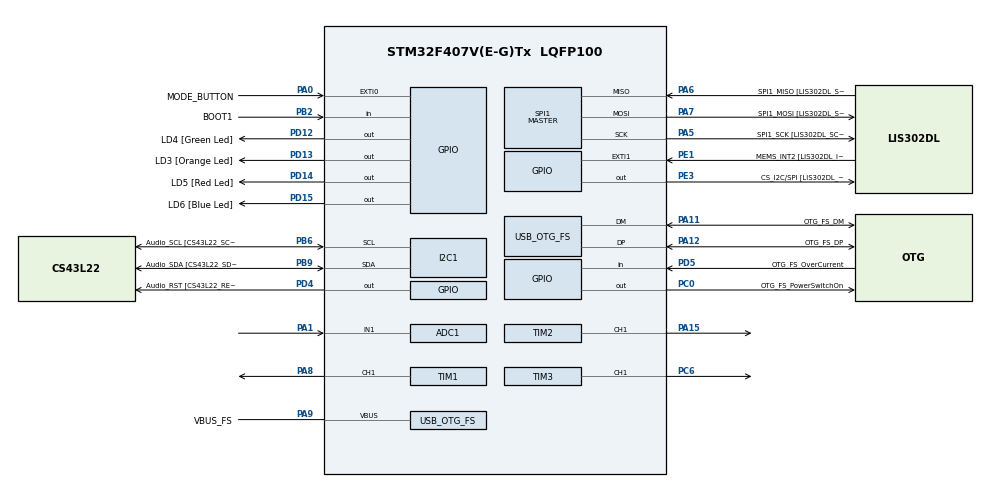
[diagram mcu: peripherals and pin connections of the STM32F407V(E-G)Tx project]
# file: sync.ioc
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ADC1.Channel-0\#ChannelRegularConversion=ADC_CHANNEL_1
ADC1.NbrOfConversionFlag=1
ADC1.Rank-0\#ChannelRegularConversion=1
ADC1.SamplingTime-0\#ChannelRegularConversion=ADC_SAMPLETIME_3CYCLES
ADC1.master=1
Dma.ADC1.1.Direction=DMA_PERIPH_TO_MEMORY
Dma.ADC1.1.FIFOMode=DMA_FIFOMODE_DISABLE
Dma.ADC1.1.Instance=DMA2_Stream0
Dma.ADC1.1.MemDataAlignment=DMA_MDATAALIGN_HALFWORD
Dma.ADC1.1.MemInc=DMA_MINC_ENABLE
Dma.ADC1.1.Mode=DMA_NORMAL
Dma.ADC1.1.PeriphDataAlignment=DMA_PDATAALIGN_HALFWORD
Dma.ADC1.1.PeriphInc=DMA_PINC_DISABLE
Dma.ADC1.1.Priority=DMA_PRIORITY_LOW
Dma.Request0=TIM1_CH1
Dma.Request1=ADC1
Dma.TIM1_CH1.0.Direction=DMA_MEMORY_TO_PERIPH
Dma.TIM1_CH1.0.FIFOMode=DMA_FIFOMODE_DISABLE
Dma.TIM1_CH1.0.Instance=DMA2_Stream1
Dma.TIM1_CH1.0.MemDataAlignment=DMA_MDATAALIGN_HALFWORD
Dma.TIM1_CH1.0.MemInc=DMA_MINC_ENABLE
Dma.TIM1_CH1.0.Mode=DMA_NORMAL
Dma.TIM1_CH1.0.PeriphDataAlignment=DMA_PDATAALIGN_HALFWORD
Dma.TIM1_CH1.0.PeriphInc=DMA_PINC_DISABLE
Dma.TIM1_CH1.0.Priority=DMA_PRIORITY_HIGH
Mcu.Family=STM32F4
Mcu.Name=STM32F407V(E-G)Tx
Mcu.Package=LQFP100
NVIC.DMA2_Stream0_IRQn=true\:0\:0\:false\:false\:true\:false\:true\:true
NVIC.DMA2_Stream1_IRQn=true\:0\:0\:false\:false\:true\:false\:true\:true
NVIC.EXTI0_IRQn=true\:0\:0\:false\:false\:true\:true\:true\:true
NVIC.OTG_FS_IRQn=true\:0\:0\:false\:false\:true\:true\:true\:true
NVIC.PriorityGroup=NVIC_PRIORITYGROUP_0
NVIC.TIM3_IRQn=true\:0\:0\:false\:false\:true\:true\:true\:true
PA0-WKUP.GPIO_Label=MODE_BUTTON
PA0-WKUP.Signal=GPXTI0
PA1.Signal=ADCx_IN1
PA10.GPIO_Label=OTG_FS_ID
PA10.GPIO_Mode=GPIO_MODE_AF_PP
PA10.GPIO_PuPd=GPIO_NOPULL
PA10.GPIO_Speed=GPIO_SPEED_FREQ_LOW
PA10.Signal=USB_OTG_FS_ID
PA11.GPIO_Label=OTG_FS_DM
PA11.GPIO_Mode=GPIO_MODE_AF_PP
PA11.GPIO_PuPd=GPIO_NOPULL
PA11.GPIO_Speed=GPIO_SPEED_FREQ_LOW
PA11.Mode=Host_Only
PA11.Signal=USB_OTG_FS_DM
PA12.GPIO_Label=OTG_FS_DP
PA12.GPIO_Mode=GPIO_MODE_AF_PP
PA12.GPIO_PuPd=GPIO_NOPULL
PA12.GPIO_Speed=GPIO_SPEED_FREQ_LOW
PA12.Mode=Host_Only
PA12.Signal=USB_OTG_FS_DP
PA13.GPIO_Label=SWDIO
PA13.Mode=Serial_Wire
PA13.Signal=SYS_JTMS-SWDIO
PA14.GPIO_Label=SWCLK
PA14.Mode=Serial_Wire
PA14.Signal=SYS_JTCK-SWCLK
PA15.Signal=S_TIM2_CH1_ETR
PA4.GPIO_Label=I2S3_WS [CS43L22_LRCK]
PA4.GPIO_Mode=GPIO_MODE_AF_PP
PA4.GPIO_PuPd=GPIO_NOPULL
PA4.GPIO_Speed=GPIO_SPEED_FREQ_LOW
PA4.Signal=I2S3_WS
PA5.GPIO_Label=SPI1_SCK [LIS302DL_SCL/SPC]
PA5.GPIO_Mode=GPIO_MODE_AF_PP
PA5.GPIO_PuPd=GPIO_NOPULL
PA5.GPIO_Speed=GPIO_SPEED_FREQ_LOW
PA5.Mode=Full_Duplex_Master
PA5.Signal=SPI1_SCK
PA6.GPIO_Label=SPI1_MISO [LIS302DL_SDO]
PA6.GPIO_Mode=GPIO_MODE_AF_PP
PA6.GPIO_PuPd=GPIO_NOPULL
PA6.GPIO_Speed=GPIO_SPEED_FREQ_LOW
PA6.Mode=Full_Duplex_Master
PA6.Signal=SPI1_MISO
PA7.GPIO_Label=SPI1_MOSI [LIS302DL_SDA/SDI/SDO]
PA7.GPIO_Mode=GPIO_MODE_AF_PP
PA7.GPIO_PuPd=GPIO_NOPULL
PA7.GPIO_Speed=GPIO_SPEED_FREQ_LOW
PA7.Mode=Full_Duplex_Master
PA7.Signal=SPI1_MOSI
PA8.Signal=S_TIM1_CH1
PA9.GPIO_Label=VBUS_FS
PA9.GPIO_Mode=GPIO_MODE_INPUT
PA9.GPIO_PuPd=GPIO_NOPULL
PA9.Mode=Activate_VBUS
PA9.Signal=USB_OTG_FS_VBUS
PB10.GPIO_Label=CLK_IN [MP45DT02_CLK]
PB10.GPIO_Mode=GPIO_MODE_AF_PP
PB10.GPIO_PuPd=GPIO_NOPULL
PB10.GPIO_Speed=GPIO_SPEED_FREQ_LOW
PB10.Signal=I2S2_CK
PB2.GPIO_Label=BOOT1
PB2.GPIO_Mode=GPIO_MODE_INPUT
PB2.GPIO_PuPd=GPIO_NOPULL
PB2.Signal=GPIO_Input
PB3.GPIO_Label=SWO
PB3.Signal=SYS_JTDO-SWO
PB6.GPIO_Label=Audio_SCL [CS43L22_SCL]
PB6.GPIO_Mode=GPIO_MODE_AF_OD
PB6.GPIO_Pu=GPIO_PULLUP
PB6.GPIO_PuPd=GPIO_NOPULL
PB6.GPIO_Speed=GPIO_SPEED_FREQ_LOW
PB6.Mode=I2C
PB6.Signal=I2C1_SCL
PB9.GPIO_Label=Audio_SDA [CS43L22_SDA]
PB9.GPIO_Mode=GPIO_MODE_AF_OD
PB9.GPIO_Pu=GPIO_PULLUP
PB9.GPIO_PuPd=GPIO_NOPULL
PB9.GPIO_Speed=GPIO_SPEED_FREQ_LOW
PB9.Mode=I2C
PB9.Signal=I2C1_SDA
PC0.GPIO_Label=OTG_FS_PowerSwitchOn
PC0.GPIO_PuPd=GPIO_NOPULL
PC0.GPIO_Speed=GPIO_SPEED_FREQ_LOW
PC0.PinState=GPIO_PIN_SET
PC0.Signal=GPIO_Output
PC10.GPIO_Label=I2S3_SCK [CS43L22_SCLK]
PC10.GPIO_Mode=GPIO_MODE_AF_PP
PC10.GPIO_PuPd=GPIO_NOPULL
PC10.GPIO_Speed=GPIO_SPEED_FREQ_LOW
PC10.Signal=I2S3_CK
PC12.GPIO_Label=I2S3_SD [CS43L22_SDIN]
PC12.GPIO_Mode=GPIO_MODE_AF_PP
PC12.GPIO_PuPd=GPIO_NOPULL
PC12.GPIO_Speed=GPIO_SPEED_FREQ_LOW
PC12.Signal=I2S3_SD
PC14-OSC32_IN.GPIO_Label=PC14-OSC32_IN
PC14-OSC32_IN.Mode=LSE-External-Oscillator
PC14-OSC32_IN.Signal=RCC_OSC32_IN
PC15-OSC32_OUT.GPIO_Label=PC15-OSC32_OUT
PC15-OSC32_OUT.Mode=LSE-External-Oscillator
PC15-OSC32_OUT.Signal=RCC_OSC32_OUT
PC3.GPIO_Label=PDM_OUT [MP45DT02_DOUT]
PC3.GPIO_Mode=GPIO_MODE_AF_PP
PC3.GPIO_PuPd=GPIO_NOPULL
PC3.GPIO_Speed=GPIO_SPEED_FREQ_LOW
PC3.Signal=I2S2_SD
PC6.Signal=S_TIM3_CH1
PC7.GPIO_Label=I2S3_MCK [CS43L22_MCLK]
PC7.GPIO_Mode=GPIO_MODE_AF_PP
PC7.GPIO_PuPd=GPIO_NOPULL
PC7.GPIO_Speed=GPIO_SPEED_FREQ_LOW
PC7.Signal=I2S3_MCK
PD12.GPIO_Label=LD4 [Green Led]
PD12.GPIO_PuPd=GPIO_NOPULL
PD12.GPIO_Speed=GPIO_SPEED_FREQ_LOW
PD12.Signal=GPIO_Output
PD13.GPIO_Label=LD3 [Orange Led]
PD13.GPIO_PuPd=GPIO_NOPULL
PD13.GPIO_Speed=GPIO_SPEED_FREQ_LOW
PD13.Signal=GPIO_Output
PD14.GPIO_Label=LD5 [Red Led]
PD14.GPIO_PuPd=GPIO_NOPULL
PD14.GPIO_Speed=GPIO_SPEED_FREQ_LOW
PD14.Signal=GPIO_Output
PD15.GPIO_Label=LD6 [Blue Led]
PD15.GPIO_PuPd=GPIO_NOPULL
PD15.GPIO_Speed=GPIO_SPEED_FREQ_LOW
PD15.Signal=GPIO_Output
PD4.GPIO_Label=Audio_RST [CS43L22_RESET]
PD4.GPIO_PuPd=GPIO_NOPULL
PD4.GPIO_Speed=GPIO_SPEED_FREQ_LOW
PD4.Signal=GPIO_Output
PD5.GPIO_Label=OTG_FS_OverCurrent
PD5.GPIO_Mode=GPIO_MODE_INPUT
PD5.GPIO_PuPd=GPIO_NOPULL
PD5.Signal=GPIO_Input
PE1.GPIO_Label=MEMS_INT2 [LIS302DL_INT2]
PE1.GPIO_ModeDefaultEXTI=GPIO_MODE_EVT_RISING
PE1.GPIO_PuPd=GPIO_NOPULL
PE1.Signal=GPXTI1
PE3.GPIO_Label=CS_I2C/SPI [LIS302DL_CS_I2C/SPI]
PE3.GPIO_PuPd=GPIO_NOPULL
PE3.GPIO_Speed=GPIO_SPEED_FREQ_LOW
PE3.Signal=GPIO_Output
PH0-OSC_IN.GPIO_Label=PH0-OSC_IN
PH0-OSC_IN.Mode=HSE-External-Oscillator
PH0-OSC_IN.Signal=RCC_OSC_IN
PH1-OSC_OUT.GPIO_Label=PH1-OSC_OUT
PH1-OSC_OUT.Mode=HSE-External-Oscillator
PH1-OSC_OUT.Signal=RCC_OSC_OUT
ProjectManager.HeapSize=0x200
ProjectManager.StackSize=0x400
ProjectManager.TargetToolchain=STM32CubeIDE
RCC.48MHZClocksFreq_Value=48000000
RCC.AHBFreq_Value=168000000
RCC.APB1CLKDivider=RCC_HCLK_DIV4
RCC.APB1Freq_Value=42000000
RCC.APB1TimFreq_Value=84000000
RCC.APB2CLKDivider=RCC_HCLK_DIV2
RCC.APB2Freq_Value=84000000
RCC.APB2TimFreq_Value=168000000
RCC.CortexFreq_Value=168000000
RCC.HCLKFreq_Value=168000000
RCC.HSE_VALUE=8000000
RCC.HSI_VALUE=16000000
RCC.PLLM=8
RCC.PLLN=336
RCC.PLLQ=7
RCC.SYSCLKFreq_VALUE=168000000
RCC.SYSCLKSource=RCC_SYSCLKSOURCE_PLLCLK
RCC.VCOOutputFreq_Value=336000000
SH.ADCx_IN1.0=ADC1_IN1,IN1
SH.S_TIM1_CH1.0=TIM1_CH1,PWM Generation1 CH1
SH.S_TIM2_CH1_ETR.0=TIM2_CH1,PWM Generation1 CH1
SH.S_TIM3_CH1.0=TIM3_CH1,PWM Generation1 CH1
SPI1.BaudRatePrescaler-Full_Duplex_Master=SPI_BAUDRATEPRESCALER_2
SPI1.CalculateBaudRate-Full_Duplex_Master=42.0 MBits/s
SPI1.Direction=SPI_DIRECTION_2LINES
SPI1.Mode=SPI_MODE_MASTER
SPI1.Mode-Full_Duplex_Master=SPI_MODE_MASTER
SPI1.VirtualType=VM_MASTER
TIM1.Channel-PWM\ Generation1\ CH1=TIM_CHANNEL_1
TIM1.Period=103
TIM2.AutoReloadPreload=TIM_AUTORELOAD_PRELOAD_ENABLE
TIM2.Channel-PWM\ Generation1\ CH1=TIM_CHANNEL_1
TIM2.Period=2248
TIM2.TIM_MasterOutputTrigger=TIM_TRGO_UPDATE
TIM3.Channel-PWM\ Generation1\ CH1=TIM_CHANNEL_1
TIM3.Period=59999
TIM3.Prescaler=41
USB_HOST.BSP.number=1
USB_HOST.USBH_HandleTypeDef-CDC_FS=hUsbHostFS
USB_HOST.VirtualModeFS=Cdc
USB_HOST0.BSP.STBoard=false
USB_HOST0.BSP.api=Unknown
USB_HOST0.BSP.instance=PC0
USB_HOST0.BSP.ip=GPIO
USB_HOST0.BSP.mode=Output
USB_HOST0.BSP.name=Drive_VBUS_FS
USB_HOST0.BSP.solution=PC0
USB_OTG_FS.VirtualMode=Host_Only
USB_OTG_FS.phy_itface=HCD_PHY_EMBEDDED
VP_TIM1_VS_ClockSourceINT.Mode=Internal
VP_TIM2_VS_ClockSourceINT.Mode=Internal
VP_TIM3_VS_ClockSourceINT.Mode=Internal
VP_USB_HOST_VS_USB_HOST_CDC_FS.Mode=CDC_FS
board=STM32F407G-DISC1

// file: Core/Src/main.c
#include "main.h"
#include "usb_host.h"

void SystemClock_Config(void);
#define TIMER_FREQ    72000000UL
#define TOTAL_CYCLES  90
#define T0H_CYCLES    30
#define T1H_CYCLES    60
#define RESET_SLOTS   50
#define MAX_LED		  84
#define USE_BRIGHTNESS 1
#define PI 3.14159265

ADC_HandleTypeDef hadc1;
DMA_HandleTypeDef hdma_adc1;
I2C_HandleTypeDef hi2c1;
SPI_HandleTypeDef hspi1;
TIM_HandleTypeDef htim1;
TIM_HandleTypeDef htim2;
TIM_HandleTypeDef htim3;
DMA_HandleTypeDef hdma_tim1_ch1;

static void MX_GPIO_Init(void);
static void MX_DMA_Init(void);
static void MX_I2C1_Init(void);
static void MX_SPI1_Init(void);
static void MX_ADC1_Init(void);
static void MX_TIM2_Init(void);
static void MX_TIM3_Init(void);
static void MX_TIM1_Init(void);
void MX_USB_HOST_Process(void);

#define LED_PER_BANDS 14
#define NUM_BANDS 6

uint8_t LED_Data[MAX_LED][4];
uint8_t LED_Mod[MAX_LED][4];

int datasentflag=0;
uint16_t pwmData[(24*MAX_LED)+50];

const uint8_t colors_pixel[14][3] = {
    {255, 0, 0},
    {255, 127, 0},
    {255, 255, 0},
    {0, 255, 0},
    {0, 255, 255},
    {0, 0, 255},
    {75, 0, 130},
    {255, 255, 255},
    {255, 182, 193},
    {255, 165, 0},
    {0, 191, 255},
    {255, 20, 147},
    {0, 128, 128},
    {128, 0, 128}
};
uint16_t effStep = 0;
uint16_t pixelPos = 0;
uint16_t colorIndex = 0;
uint16_t fadeStep = 0;

typedef enum {
    MODE_RAINBOW,
	MODE_FFT
} EffectMode;

EffectMode mode = MODE_RAINBOW;

uint8_t tick_divider,  count_tick = 0;
volatile uint8_t call_effect_flag= 0;

void HAL_TIM_PeriodElapsedCallback(TIM_HandleTypeDef *htim);
void HAL_TIM_PWM_PulseFinishedCallback(TIM_HandleTypeDef *htim);

void Set_Brightness (int brightness);
void Set_LED (int LEDnum, int Red, int Green, int Blue) ;
void Reset_LED (void);
void WS2812_Send(void);

uint8_t rainbow_effect();
uint8_t sync_effect();

//------------ Audio management section-----------------
#define ADC_MEAN   2048.0f
extern ADC_HandleTypeDef hadc1;

#define FFT_SIZE 256
uint16_t audioBuffer[FFT_SIZE * 2]; // 2 ping pong buffer
volatile uint8_t ready_buffer = 0;
volatile uint8_t current_buffer = 0;
//------------ End Audio management section-----------------
//-------------FFT define section----------------
#define ARM_MATH_CM4
#include "arm_math.h"

#define SAMPLE_RATE 8000

arm_rfft_fast_instance_f32 fftInstance;

typedef struct {
    uint16_t start_bin;
    uint16_t end_bin;
    float magnitude;
    uint8_t color[3];
} FrequencyBand;

FrequencyBand frequency_bands[NUM_BANDS];

float band_frequencies[NUM_BANDS + 1] = {
    20,    // end low bass, start bass
    150,
	250,   // end bass, start upper bass
	500,
    1000,   // end upper bass, start low mid
    2000,  // end low mid, start mid
    4000,  // end mid, start high mid
};
const uint8_t band_colors[NUM_BANDS][3] = {
    {255, 0, 0},    // Band 0: Red (Bass)
    {255, 127, 0},  // Band 1: Orange
    {255, 255, 0},  // Band 2: Yellow
    {0, 255, 0},    // Band 3: Green
    {0, 255, 255},  // Band 4: Cyan
    {0, 0, 255}     // Band 5: Blue
};

void FFT_INIT(void);
void FFT_PROCESS(void);
//-------------END FFT define section----------------

/**
 * @brief  Bass-reactive pulse: brightness & color based on sound level.
 * @retval 0x01 always, 0x00 on ADC error.
 */

#include <stdbool.h>
/**
 * @brief  Invoked by TIM3 interrupt: selects and runs current effect.
 */
void call_effect(void)
{

    call_effect_flag = 0;
    switch (mode)
    {
        case MODE_RAINBOW:
            tick_divider = 10;
            rainbow_effect();
            break;

        case MODE_FFT:
        	sync_effect();
            break;

        default:
            break;
    }
}
  // Bắt đầu chuyển đổi ADC để đọc cường độ âm thanh
//  HAL_ADC_Start(&hadc1);

  /* USER CODE END 2 */
  int main(void) {
	  HAL_Init();
	  SystemClock_Config();
	  MX_GPIO_Init();
	  MX_DMA_Init();
	  MX_I2C1_Init();
	  MX_SPI1_Init();
	  MX_USB_HOST_Init();
	  MX_ADC1_Init();
	  MX_TIM2_Init();
	  MX_TIM1_Init();
	  MX_TIM3_Init();

	  HAL_TIM_Base_Start(&htim2);
	  HAL_TIM_Base_Start_IT(&htim3);
	  FFT_INIT();
	  Reset_LED();
	  HAL_ADC_Start_DMA(&hadc1, (uint32_t*)audioBuffer, FFT_SIZE);

      mode = MODE_RAINBOW;

      while (1)
      {
          if (call_effect_flag)
        	  call_effect();

          HAL_Delay(5);
      }
  }

 // ===========LED transmission section ===========
void WS2812_Send(void) {
      uint32_t indx = 0;
      uint32_t color;

      for (int led = 0; led < MAX_LED; led++) {
  #if USE_BRIGHTNESS
          color = ((LED_Mod[led][1]<<16) | (LED_Mod[led][2]<<8) | LED_Mod[led][3]);
  #else
          color = ((LED_Data[led][1]<<16) | (LED_Data[led][2]<<8) | LED_Data[led][3]);
  #endif
          for (int bit = 23; bit >= 0; bit--) {
              pwmData[indx++] = (color & (1UL << bit)) ? T1H_CYCLES : T0H_CYCLES;
          }
      }

      for (int i = 0; i < RESET_SLOTS; i++) {
          pwmData[indx++] = 0;
      }

      HAL_GPIO_TogglePin(GPIOA, GPIO_PIN_5);
      HAL_TIM_PWM_Start_DMA(&htim1, TIM_CHANNEL_1, (uint32_t *)pwmData, indx);
      while (!datasentflag) {}
      datasentflag = 0;
}
void Reset_LED (void) {
      for (int i=0; i< MAX_LED; i++) {
    	  LED_Mod[i][0] = i;
          LED_Mod[i][1] = 0;
          LED_Mod[i][2] = 0;
          LED_Mod[i][3] = 0;
      }
}
void Set_Brightness (int brightness) {
#if USE_BRIGHTNESS
    if (brightness > 45) brightness = 45;
    for (int i=0; i < MAX_LED; i++) {
        LED_Mod[i][0] = LED_Data[i][0];
        for (int j=1; j<4; j++) {
            float angle = 90-brightness;
            angle = angle*PI / 180;
            LED_Mod[i][j] = (LED_Data[i][j])/(tan(angle));
        }
    }
#endif
}
void Set_LED (int LEDnum, int Red, int Green, int Blue) {
    LED_Mod[LEDnum][0] = LEDnum;
    LED_Mod[LEDnum][1] = Green;
    LED_Mod[LEDnum][2] = Red;
    LED_Mod[LEDnum][3] = Blue;
}
// ===========END LED transmission section===========
// ===========Custom callback section ================
void HAL_ADC_ConvCpltCallback(ADC_HandleTypeDef* hadc)
{
	current_buffer = !current_buffer;
	ready_buffer = 1;
	HAL_ADC_Start_DMA(&hadc1, (uint32_t*)&audioBuffer[current_buffer * FFT_SIZE], FFT_SIZE);
}

void HAL_TIM_PWM_PulseFinishedCallback(TIM_HandleTypeDef *htim) {
    HAL_TIM_PWM_Stop_DMA(&htim1, TIM_CHANNEL_1);
    datasentflag=1;
}
void HAL_TIM_PeriodElapsedCallback(TIM_HandleTypeDef *htim) {
		count_tick++;
	if (htim->Instance == TIM3 && tick_divider == count_tick ) {
		count_tick = 0;
		call_effect_flag = 1;

	}
}
void HAL_GPIO_EXTI_Callback(uint16_t GPIO_Pin)
{
      if(GPIO_Pin == GPIO_PIN_0) // INT Source is pin A9
      {
    	  mode = (EffectMode)((mode + 1) % 2);
      }
}
// =========== End Custom callback section===========
// =========== LED effect section ==================
uint8_t rainbow_effect() {
	    // Strip ID: 0 - Effect: Rainbow - LEDS: 8
	    // Steps: 13 - Delay: 54
	    // Colors: 3 (255.0.0, 0.255.0, 0.0.255)
	    // Options: rainbowlen=8, toLeft=true,
	//  if(millis() - strip_0.effStart < 54 * (strip_0.effStep)) return 0x00;

	  float factor1, factor2;
	  uint16_t ind;
	  for(uint16_t j=0;j< MAX_LED;j++) {
	    ind = effStep + j * 1.625;
	    switch((int)((ind % 13) / 4.333333333333333)) {
	      case 0: factor1 = 1.0 - ((float)(ind % 13 - 0 * 4.333333333333333) / 4.333333333333333);
	              factor2 = (float)((int)(ind - 0) % 13) / 4.333333333333333;
	              /************ chnaged here *********/
	              Set_LED(j, 255 * factor1 + 0 * factor2, 0 * factor1 + 255 * factor2, 0 * factor1 + 0 * factor2);
	              WS2812_Send();
	              break;
	      case 1: factor1 = 1.0 - ((float)(ind % 13 - 1 * 4.333333333333333) / 4.333333333333333);
	              factor2 = (float)((int)(ind - 4.333333333333333) % 13) / 4.333333333333333;
	              Set_LED(j, 0 * factor1 + 0 * factor2, 255 * factor1 + 0 * factor2, 0 * factor1 + 255 * factor2);
	              WS2812_Send();
	              break;
	      case 2: factor1 = 1.0 - ((float)(ind % 13 - 2 * 4.333333333333333) / 4.333333333333333);
	              factor2 = (float)((int)(ind - 8.666666666666666) % 13) / 4.333333333333333;
	              Set_LED(j, 0 * factor1 + 255 * factor2, 0 * factor1 + 0 * factor2, 255 * factor1 + 0 * factor2);
	              WS2812_Send();
	              break;
	    }
	  }
	  if(effStep >= 13) {effStep=0; return 0x03; }
	  else effStep++;
	  return 0x01;
	}
//----------------FFT subsection-----------------------
void FFT_INIT(void)
{
	arm_rfft_fast_init_f32(&fftInstance, FFT_SIZE);
	float freq_resolution = (float)SAMPLE_RATE / FFT_SIZE;

	for (int i = 0; i < NUM_BANDS; i++) {
	        frequency_bands[i].start_bin = (uint16_t)(band_frequencies[i] / freq_resolution);
	        frequency_bands[i].end_bin = (uint16_t)(band_frequencies[i + 1] / freq_resolution);
	        frequency_bands[i].magnitude = 0.0f;

	        frequency_bands[i].color[0] = band_colors[i][0];
	        frequency_bands[i].color[1] = band_colors[i][1];
	        frequency_bands[i].color[2] = band_colors[i][2];

	        if (frequency_bands[i].end_bin > FFT_SIZE/2)
	            frequency_bands[i].end_bin = FFT_SIZE/2;
	}
}

void FFT_PROCESS(void)
{
	float32_t inputBuffer[FFT_SIZE * 2],
			 outputBuffer[FFT_SIZE];
	float32_t fftBuffer[FFT_SIZE * 2];
	for (int i = 0; i < FFT_SIZE; i++) {
	        inputBuffer[i] = ((float32_t)audioBuffer[(!current_buffer) * FFT_SIZE + i] -  ADC_MEAN);
	        // normalize signal
	        inputBuffer[i] /= ADC_MEAN;
	    }
	    // Biến đổi RFFT
	    arm_rfft_fast_f32(&fftInstance, inputBuffer, fftBuffer, 0);

	    // Tính cường độ
	    arm_cmplx_mag_f32(fftBuffer, outputBuffer, FFT_SIZE / 2);
	    // TÍnh trung bình cường độ của mỗi band
	    for (int band = 0; band < NUM_BANDS; band++) {
	        float sum = 0.0f;
	        int bin_count = 0;

	        for (int bin = frequency_bands[band].start_bin; bin < frequency_bands[band].end_bin; bin++) {
	            if (bin < FFT_SIZE / 2) {
	                sum += outputBuffer[bin];
	                bin_count++;
	            }
	        }
	        float avg =  sum / bin_count;
	        if (bin_count > 0) {
	            frequency_bands[band].magnitude = avg;
	        }
	    }
	}

const float max_magnitude[NUM_BANDS] = {20.0f, 20.0f, 20.0f, 20.0f, 15.0f, 10.0f};
const float min_magnitude[NUM_BANDS] = {5.0f, 5.0f, 5.0f, 5.0, 2.5f, 1.0f};

uint8_t top_index[NUM_BANDS] ={0};

uint8_t sync_effect()
{
    if (!ready_buffer)
        return 0;

    FFT_PROCESS();
    ready_buffer = 0;

    const int leds_per_band = 14;
    for (int band = 0; band < NUM_BANDS; band++)
    {
        float magnitude = frequency_bands[band].magnitude;
        float max  = max_magnitude[band];
        // Clamp magnitude
        if (magnitude < 0.0f) magnitude = 0.0f;
        if (magnitude > max_magnitude[band]) magnitude = max_magnitude[band];

        // Calculate activate led
        int active_leds = (int)((magnitude / max) * leds_per_band);
        if (active_leds > leds_per_band) active_leds = leds_per_band;

        uint8_t r = (uint8_t)(band_colors[band][0]);
        uint8_t g = (uint8_t)(band_colors[band][1]);
        uint8_t b = (uint8_t)(band_colors[band][2]);

        if (top_index[band] <= active_leds)
        	top_index[band] = active_leds;
        else
        	top_index[band]--;
        // Bật LED theo cường độ
        for (int i = 0; i < leds_per_band; i++) {
            int led_index = leds_per_band * band + i;
            if (i < active_leds) {
                Set_LED(led_index, r, g, b);
            } else {
                Set_LED(led_index, 0, 0, 0);
            }
        }
        Set_LED(top_index[band], 155 , 155 , 155);
        WS2812_Send();
        HAL_Delay(5);
    }

    return 1;
}

  void SystemClock_Config(void)
  {
    RCC_OscInitTypeDef RCC_OscInitStruct = {0};
    RCC_ClkInitTypeDef RCC_ClkInitStruct = {0};

    /** Configure the main internal regulator output voltage
    */
    __HAL_RCC_PWR_CLK_ENABLE();
    __HAL_PWR_VOLTAGESCALING_CONFIG(PWR_REGULATOR_VOLTAGE_SCALE1);
    /** Initializes the RCC Oscillators according to the specified parameters
    * in the RCC_OscInitTypeDef structure.
    */
    RCC_OscInitStruct.OscillatorType = RCC_OSCILLATORTYPE_HSE;
    RCC_OscInitStruct.HSEState = RCC_HSE_BYPASS;
    RCC_OscInitStruct.PLL.PLLState = RCC_PLL_ON;
    RCC_OscInitStruct.PLL.PLLSource = RCC_PLLSOURCE_HSE;
    RCC_OscInitStruct.PLL.PLLM = 4;
    RCC_OscInitStruct.PLL.PLLN = 72;
    RCC_OscInitStruct.PLL.PLLP = RCC_PLLP_DIV2;
    RCC_OscInitStruct.PLL.PLLQ = 2;
//    RCC_OscInitStruct.PLL.PLLM = 2;
    if (HAL_RCC_OscConfig(&RCC_OscInitStruct) != HAL_OK)
    {
      Error_Handler();
    }
    /** Initializes the CPU, AHB and APB buses clocks
    */
    RCC_ClkInitStruct.ClockType = RCC_CLOCKTYPE_HCLK|RCC_CLOCKTYPE_SYSCLK
                                |RCC_CLOCKTYPE_PCLK1|RCC_CLOCKTYPE_PCLK2;
    RCC_ClkInitStruct.SYSCLKSource = RCC_SYSCLKSOURCE_PLLCLK;
    RCC_ClkInitStruct.AHBCLKDivider = RCC_SYSCLK_DIV1;
    RCC_ClkInitStruct.APB1CLKDivider = RCC_HCLK_DIV2;
    RCC_ClkInitStruct.APB2CLKDivider = RCC_HCLK_DIV1;

    if (HAL_RCC_ClockConfig(&RCC_ClkInitStruct, FLASH_LATENCY_2) != HAL_OK)
    {
      Error_Handler();
    }
  }
static void MX_ADC1_Init(void)
{
	ADC_ChannelConfTypeDef sConfig = {0};

	    hadc1.Instance = ADC1;
	    hadc1.Init.ClockPrescaler = ADC_CLOCK_SYNC_PCLK_DIV4;      // ADC clock = 72MHz/4 = 18MHz
	    hadc1.Init.Resolution = ADC_RESOLUTION_12B;
	    hadc1.Init.ScanConvMode = DISABLE;
	    hadc1.Init.ContinuousConvMode = DISABLE;
	    hadc1.Init.DiscontinuousConvMode = DISABLE;
	    hadc1.Init.ExternalTrigConvEdge = ADC_EXTERNALTRIGCONVEDGE_RISING;
	    hadc1.Init.ExternalTrigConv = ADC_EXTERNALTRIGCONV_T2_TRGO; // Trigger từ TIM2
	    hadc1.Init.DataAlign = ADC_DATAALIGN_RIGHT;
	    hadc1.Init.NbrOfConversion = 1;
	    hadc1.Init.DMAContinuousRequests = ENABLE;                 // Cho phép DMA Circular
	    hadc1.Init.EOCSelection = ADC_EOC_SINGLE_CONV;
	    if (HAL_ADC_Init(&hadc1) != HAL_OK)
	    {
	        Error_Handler();
	    }

	    sConfig.Channel = ADC_CHANNEL_1;                  // Kênh ADC1_IN1 (PA1)
	    sConfig.Rank = 1;
	    sConfig.SamplingTime = ADC_SAMPLETIME_28CYCLES;   // 28 cycles
	    if (HAL_ADC_ConfigChannel(&hadc1, &sConfig) != HAL_OK)
	    {
	        Error_Handler();
	    }
}

static void MX_I2C1_Init(void)
{

  hi2c1.Instance = I2C1;
  hi2c1.Init.ClockSpeed = 100000;
  hi2c1.Init.DutyCycle = I2C_DUTYCYCLE_2;
  hi2c1.Init.OwnAddress1 = 0;
  hi2c1.Init.AddressingMode = I2C_ADDRESSINGMODE_7BIT;
  hi2c1.Init.DualAddressMode = I2C_DUALADDRESS_DISABLE;
  hi2c1.Init.OwnAddress2 = 0;
  hi2c1.Init.GeneralCallMode = I2C_GENERALCALL_DISABLE;
  hi2c1.Init.NoStretchMode = I2C_NOSTRETCH_DISABLE;
  if (HAL_I2C_Init(&hi2c1) != HAL_OK)
  {
    Error_Handler();
  }

}

static void MX_SPI1_Init(void)
{

  hspi1.Instance = SPI1;
  hspi1.Init.Mode = SPI_MODE_MASTER;
  hspi1.Init.Direction = SPI_DIRECTION_2LINES;
  hspi1.Init.DataSize = SPI_DATASIZE_8BIT;
  hspi1.Init.CLKPolarity = SPI_POLARITY_LOW;
  hspi1.Init.CLKPhase = SPI_PHASE_1EDGE;
  hspi1.Init.NSS = SPI_NSS_SOFT;
  hspi1.Init.BaudRatePrescaler = SPI_BAUDRATEPRESCALER_2;
  hspi1.Init.FirstBit = SPI_FIRSTBIT_MSB;
  hspi1.Init.TIMode = SPI_TIMODE_DISABLE;
  hspi1.Init.CRCCalculation = SPI_CRCCALCULATION_DISABLE;
  hspi1.Init.CRCPolynomial = 10;
  if (HAL_SPI_Init(&hspi1) != HAL_OK)
  {
    Error_Handler();
  }

}

static void MX_TIM1_Init(void)
{

  TIM_ClockConfigTypeDef sClockSourceConfig = {0};
  TIM_MasterConfigTypeDef sMasterConfig = {0};
  TIM_OC_InitTypeDef sConfigOC = {0};
  TIM_BreakDeadTimeConfigTypeDef sBreakDeadTimeConfig = {0};

  htim1.Instance = TIM1;
  htim1.Init.Prescaler = 0;
  htim1.Init.CounterMode = TIM_COUNTERMODE_UP;
  htim1.Init.Period = 90-1;
  htim1.Init.ClockDivision = TIM_CLOCKDIVISION_DIV1;
  htim1.Init.RepetitionCounter = 0;
  htim1.Init.AutoReloadPreload = TIM_AUTORELOAD_PRELOAD_DISABLE;
  if (HAL_TIM_Base_Init(&htim1) != HAL_OK)
  {
    Error_Handler();
  }
  sClockSourceConfig.ClockSource = TIM_CLOCKSOURCE_INTERNAL;
  if (HAL_TIM_ConfigClockSource(&htim1, &sClockSourceConfig) != HAL_OK)
  {
    Error_Handler();
  }
  if (HAL_TIM_PWM_Init(&htim1) != HAL_OK)
  {
    Error_Handler();
  }
  sMasterConfig.MasterOutputTrigger = TIM_TRGO_RESET;
  sMasterConfig.MasterSlaveMode = TIM_MASTERSLAVEMODE_DISABLE;
  if (HAL_TIMEx_MasterConfigSynchronization(&htim1, &sMasterConfig) != HAL_OK)
  {
    Error_Handler();
  }
  sConfigOC.OCMode = TIM_OCMODE_PWM1;
  sConfigOC.Pulse = 0;
  sConfigOC.OCPolarity = TIM_OCPOLARITY_HIGH;
  sConfigOC.OCNPolarity = TIM_OCNPOLARITY_HIGH;
  sConfigOC.OCFastMode = TIM_OCFAST_DISABLE;
  sConfigOC.OCIdleState = TIM_OCIDLESTATE_RESET;
  sConfigOC.OCNIdleState = TIM_OCNIDLESTATE_RESET;
  if (HAL_TIM_PWM_ConfigChannel(&htim1, &sConfigOC, TIM_CHANNEL_1) != HAL_OK)
  {
    Error_Handler();
  }
  sBreakDeadTimeConfig.OffStateRunMode = TIM_OSSR_DISABLE;
  sBreakDeadTimeConfig.OffStateIDLEMode = TIM_OSSI_DISABLE;
  sBreakDeadTimeConfig.LockLevel = TIM_LOCKLEVEL_OFF;
  sBreakDeadTimeConfig.DeadTime = 0;
  sBreakDeadTimeConfig.BreakState = TIM_BREAK_DISABLE;
  sBreakDeadTimeConfig.BreakPolarity = TIM_BREAKPOLARITY_HIGH;
  sBreakDeadTimeConfig.AutomaticOutput = TIM_AUTOMATICOUTPUT_DISABLE;
  if (HAL_TIMEx_ConfigBreakDeadTime(&htim1, &sBreakDeadTimeConfig) != HAL_OK)
  {
    Error_Handler();
  }
  HAL_TIM_MspPostInit(&htim1);

}

static void MX_TIM2_Init(void)
{
    TIM_ClockConfigTypeDef sClockSourceConfig = {0};
    TIM_MasterConfigTypeDef sMasterConfig = {0};

    htim2.Instance = TIM2;
    htim2.Init.Prescaler = 71;                   // 72MHz/72 = 1MHz
    htim2.Init.CounterMode = TIM_COUNTERMODE_UP;
    htim2.Init.Period = 124;                     // 1MHz/125 = 8000Hz → mỗi 125µs overflow
    htim2.Init.ClockDivision = TIM_CLOCKDIVISION_DIV1;
    htim2.Init.AutoReloadPreload = TIM_AUTORELOAD_PRELOAD_DISABLE;
    if (HAL_TIM_Base_Init(&htim2) != HAL_OK)
    {
        Error_Handler();
    }
    sClockSourceConfig.ClockSource = TIM_CLOCKSOURCE_INTERNAL;
    if (HAL_TIM_ConfigClockSource(&htim2, &sClockSourceConfig) != HAL_OK)
    {
        Error_Handler();
    }
    // Cho TIM2 tạo TRGO mỗi khi counter overflow (update event)
    sMasterConfig.MasterOutputTrigger = TIM_TRGO_UPDATE;
    sMasterConfig.MasterSlaveMode = TIM_MASTERSLAVEMODE_DISABLE;
    if (HAL_TIMEx_MasterConfigSynchronization(&htim2, &sMasterConfig) != HAL_OK)
    {
        Error_Handler();
    }
}

static void MX_TIM3_Init(void)
{

  TIM_ClockConfigTypeDef sClockSourceConfig = {0};
  TIM_MasterConfigTypeDef sMasterConfig = {0};
  TIM_OC_InitTypeDef sConfigOC = {0};
  TIM_BreakDeadTimeConfigTypeDef sBreakDeadTimeConfig = {0};

  htim3.Instance = TIM3;
  htim3.Init.Prescaler = 1;
  htim3.Init.CounterMode = TIM_COUNTERMODE_UP;
  htim3.Init.Period = 39999;
  htim3.Init.ClockDivision = TIM_CLOCKDIVISION_DIV1;
  htim3.Init.RepetitionCounter = 0;
  htim3.Init.AutoReloadPreload = TIM_AUTORELOAD_PRELOAD_ENABLE;
  if (HAL_TIM_Base_Init(&htim3) != HAL_OK)
  {
    Error_Handler();
  }
  sClockSourceConfig.ClockSource = TIM_CLOCKSOURCE_INTERNAL;
  if (HAL_TIM_ConfigClockSource(&htim3, &sClockSourceConfig) != HAL_OK)
  {
    Error_Handler();
  }
  if (HAL_TIM_PWM_Init(&htim3) != HAL_OK)
  {
    Error_Handler();
  }
  sMasterConfig.MasterOutputTrigger = TIM_TRGO_RESET;
  sMasterConfig.MasterSlaveMode = TIM_MASTERSLAVEMODE_DISABLE;
  if (HAL_TIMEx_MasterConfigSynchronization(&htim3, &sMasterConfig) != HAL_OK)
  {
    Error_Handler();
  }
  sConfigOC.OCMode = TIM_OCMODE_PWM1;
  sConfigOC.Pulse = 0;
  sConfigOC.OCPolarity = TIM_OCPOLARITY_HIGH;
  sConfigOC.OCNPolarity = TIM_OCNPOLARITY_HIGH;
  sConfigOC.OCFastMode = TIM_OCFAST_DISABLE;
  sConfigOC.OCIdleState = TIM_OCIDLESTATE_RESET;
  sConfigOC.OCNIdleState = TIM_OCNIDLESTATE_RESET;
  if (HAL_TIM_PWM_ConfigChannel(&htim3, &sConfigOC, TIM_CHANNEL_1) != HAL_OK)
  {
    Error_Handler();
  }
  sBreakDeadTimeConfig.OffStateRunMode = TIM_OSSR_DISABLE;
  sBreakDeadTimeConfig.OffStateIDLEMode = TIM_OSSI_DISABLE;
  sBreakDeadTimeConfig.LockLevel = TIM_LOCKLEVEL_OFF;
  sBreakDeadTimeConfig.DeadTime = 0;
  sBreakDeadTimeConfig.BreakState = TIM_BREAK_DISABLE;
  sBreakDeadTimeConfig.BreakPolarity = TIM_BREAKPOLARITY_HIGH;
  sBreakDeadTimeConfig.AutomaticOutput = TIM_AUTOMATICOUTPUT_DISABLE;
  if (HAL_TIMEx_ConfigBreakDeadTime(&htim3, &sBreakDeadTimeConfig) != HAL_OK)
  {
    Error_Handler();
  }
  HAL_TIM_MspPostInit(&htim1);

}

static void MX_DMA_Init(void)
{

  /* DMA controller clock enable */
  __HAL_RCC_DMA2_CLK_ENABLE();

  /* DMA interrupt init */
	  hdma_adc1.Instance = DMA2_Stream0;  // or another available stream
	  hdma_adc1.Init.Channel = DMA_CHANNEL_0;
	  hdma_adc1.Init.Direction = DMA_PERIPH_TO_MEMORY;
	  hdma_adc1.Init.PeriphInc = DMA_PINC_DISABLE;
	  hdma_adc1.Init.MemInc = DMA_MINC_ENABLE;
	  hdma_adc1.Init.PeriphDataAlignment = DMA_PDATAALIGN_HALFWORD;
	  hdma_adc1.Init.MemDataAlignment = DMA_MDATAALIGN_HALFWORD;
	  hdma_adc1.Init.Mode = DMA_CIRCULAR;
	  hdma_adc1.Init.Priority = DMA_PRIORITY_HIGH;
	  hdma_adc1.Init.FIFOMode = DMA_FIFOMODE_DISABLE;

	    if (HAL_DMA_Init(&hdma_adc1) != HAL_OK) {
	        Error_Handler();
	    }
	    __HAL_LINKDMA(&hadc1, DMA_Handle, hdma_adc1);

	  hdma_tim1_ch1.Instance                 = DMA2_Stream1;
      hdma_tim1_ch1.Init.Channel             = DMA_CHANNEL_6;
      hdma_tim1_ch1.Init.Direction           = DMA_MEMORY_TO_PERIPH;
      hdma_tim1_ch1.Init.PeriphInc           = DMA_PINC_DISABLE;
      hdma_tim1_ch1.Init.MemInc              = DMA_MINC_ENABLE;
      hdma_tim1_ch1.Init.PeriphDataAlignment = DMA_PDATAALIGN_HALFWORD;
      hdma_tim1_ch1.Init.MemDataAlignment    = DMA_MDATAALIGN_HALFWORD;
      hdma_tim1_ch1.Init.Mode                = DMA_NORMAL;
      hdma_tim1_ch1.Init.Priority            = DMA_PRIORITY_HIGH;
      hdma_tim1_ch1.Init.FIFOMode            = DMA_FIFOMODE_DISABLE;
      if (HAL_DMA_Init(&hdma_tim1_ch1) != HAL_OK)
      {
        Error_Handler();
      }

      __HAL_LINKDMA(&htim1, hdma[TIM_DMA_ID_CC1], hdma_tim1_ch1);
  /* DMA2_Stream0_IRQn interrupt configuration */
  HAL_NVIC_SetPriority(DMA2_Stream0_IRQn, 0, 0);
  HAL_NVIC_EnableIRQ(DMA2_Stream0_IRQn);
  /* DMA2_Stream1_IRQn interrupt configuration */
  HAL_NVIC_SetPriority(DMA2_Stream1_IRQn, 0, 0);
  HAL_NVIC_EnableIRQ(DMA2_Stream1_IRQn);

}

static void MX_GPIO_Init(void)
{
  GPIO_InitTypeDef GPIO_InitStruct = {0};

  /* GPIO Ports Clock Enable */
  __HAL_RCC_GPIOE_CLK_ENABLE();
  __HAL_RCC_GPIOC_CLK_ENABLE();
  __HAL_RCC_GPIOH_CLK_ENABLE();
  __HAL_RCC_GPIOA_CLK_ENABLE();
  __HAL_RCC_GPIOB_CLK_ENABLE();
  __HAL_RCC_GPIOD_CLK_ENABLE();

  /*Configure GPIO pin Output Level */
  HAL_GPIO_WritePin(CS_I2C_SPI_GPIO_Port, CS_I2C_SPI_Pin, GPIO_PIN_RESET);

  /*Configure GPIO pin Output Level */
  HAL_GPIO_WritePin(OTG_FS_PowerSwitchOn_GPIO_Port, OTG_FS_PowerSwitchOn_Pin, GPIO_PIN_SET);

  /*Configure GPIO pin Output Level */
  HAL_GPIO_WritePin(GPIOD, LD4_Pin |Audio_RST_Pin, GPIO_PIN_RESET);

  /*Configure GPIO pin : CS_I2C_SPI_Pin */
  GPIO_InitStruct.Pin = CS_I2C_SPI_Pin;
  GPIO_InitStruct.Mode = GPIO_MODE_OUTPUT_PP;
  GPIO_InitStruct.Pull = GPIO_NOPULL;
  GPIO_InitStruct.Speed = GPIO_SPEED_FREQ_LOW;
  HAL_GPIO_Init(CS_I2C_SPI_GPIO_Port, &GPIO_InitStruct);

  /*Configure GPIO pin : OTG_FS_PowerSwitchOn_Pin */
  GPIO_InitStruct.Pin = OTG_FS_PowerSwitchOn_Pin;
  GPIO_InitStruct.Mode = GPIO_MODE_OUTPUT_PP;
  GPIO_InitStruct.Pull = GPIO_NOPULL;
  GPIO_InitStruct.Speed = GPIO_SPEED_FREQ_LOW;
  HAL_GPIO_Init(OTG_FS_PowerSwitchOn_GPIO_Port, &GPIO_InitStruct);

  /*Configure GPIO pin : PDM_OUT_Pin */
  GPIO_InitStruct.Pin = PDM_OUT_Pin;
  GPIO_InitStruct.Mode = GPIO_MODE_AF_PP;
  GPIO_InitStruct.Pull = GPIO_NOPULL;
  GPIO_InitStruct.Speed = GPIO_SPEED_FREQ_LOW;
  GPIO_InitStruct.Alternate = GPIO_AF5_SPI2;
  HAL_GPIO_Init(PDM_OUT_GPIO_Port, &GPIO_InitStruct);

  GPIO_InitStruct.Pin = GPIO_PIN_0;
  GPIO_InitStruct.Mode = GPIO_MODE_IT_RISING;
  GPIO_InitStruct.Pull = GPIO_NOPULL;
  HAL_GPIO_Init(GPIOA, &GPIO_InitStruct);

  /*Configure GPIO pin : I2S3_WS_Pin */
  GPIO_InitStruct.Pin = I2S3_WS_Pin;
  GPIO_InitStruct.Mode = GPIO_MODE_AF_PP;
  GPIO_InitStruct.Pull = GPIO_NOPULL;
  GPIO_InitStruct.Speed = GPIO_SPEED_FREQ_LOW;
  GPIO_InitStruct.Alternate = GPIO_AF6_SPI3;
  HAL_GPIO_Init(I2S3_WS_GPIO_Port, &GPIO_InitStruct);

  /*Configure GPIO pin : BOOT1_Pin */
  GPIO_InitStruct.Pin = BOOT1_Pin;
  GPIO_InitStruct.Mode = GPIO_MODE_INPUT;
  GPIO_InitStruct.Pull = GPIO_NOPULL;
  HAL_GPIO_Init(BOOT1_GPIO_Port, &GPIO_InitStruct);

  /*Configure GPIO pin : CLK_IN_Pin */
  GPIO_InitStruct.Pin = CLK_IN_Pin;
  GPIO_InitStruct.Mode = GPIO_MODE_AF_PP;
  GPIO_InitStruct.Pull = GPIO_NOPULL;
  GPIO_InitStruct.Speed = GPIO_SPEED_FREQ_LOW;
  GPIO_InitStruct.Alternate = GPIO_AF5_SPI2;
  HAL_GPIO_Init(CLK_IN_GPIO_Port, &GPIO_InitStruct);

  /*Configure GPIO pins : LD4_Pin LD3_Pin LD5_Pin LD6_Pin
                           Audio_RST_Pin */
  GPIO_InitStruct.Pin = LD4_Pin
                          |Audio_RST_Pin;
  GPIO_InitStruct.Mode = GPIO_MODE_OUTPUT_PP;
  GPIO_InitStruct.Pull = GPIO_NOPULL;
  GPIO_InitStruct.Speed = GPIO_SPEED_FREQ_LOW;
  HAL_GPIO_Init(GPIOD, &GPIO_InitStruct);

  /*Configure GPIO pin : OTG_FS_OverCurrent_Pin */
  GPIO_InitStruct.Pin = OTG_FS_OverCurrent_Pin;
  GPIO_InitStruct.Mode = GPIO_MODE_INPUT;
  GPIO_InitStruct.Pull = GPIO_NOPULL;
  HAL_GPIO_Init(OTG_FS_OverCurrent_GPIO_Port, &GPIO_InitStruct);

  /*Configure GPIO pin : MEMS_INT2_Pin */
  GPIO_InitStruct.Pin = MEMS_INT2_Pin;
  GPIO_InitStruct.Mode = GPIO_MODE_EVT_RISING;
  GPIO_InitStruct.Pull = GPIO_NOPULL;
  HAL_GPIO_Init(MEMS_INT2_GPIO_Port, &GPIO_InitStruct);

/* USER CODE BEGIN MX_GPIO_Init_2 */
  HAL_NVIC_SetPriority(EXTI0_IRQn , 0, 0);
  HAL_NVIC_EnableIRQ(EXTI0_IRQn);

  HAL_NVIC_SetPriority(TIM3_IRQn, 0, 0);
  HAL_NVIC_EnableIRQ(TIM3_IRQn);

/* USER CODE END MX_GPIO_Init_2 */
}

void Error_Handler(void)
{
  __disable_irq();
  while (1)
  {
  }
}
